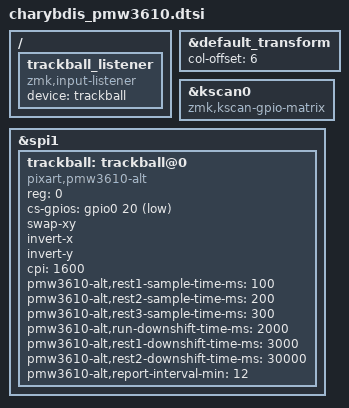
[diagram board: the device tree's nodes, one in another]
#include "charybdis.dtsi"
// #include "charybdis_pmw3610.dtsi"  <-- если в нём остался узел trackball, лучше убрать

&default_transform {
	col-offset = <6>;
};

&kscan0 {
	compatible = "zmk,kscan-gpio-matrix";
	// оставь свои col-gpios/row-gpios как было
};

// Трекбол на SPI1, не на SPI0
&spi1 {
    status = "okay";

    trackball: trackball@0 {
        compatible = "pixart,pmw3610-alt";
        reg = <0>;
        cs-gpios = <&gpio0 20 GPIO_ACTIVE_LOW>;

        swap-xy;
        invert-x;
        invert-y;

        cpi = <1600>;

        pmw3610-alt,rest1-sample-time-ms = <100>;
        pmw3610-alt,rest2-sample-time-ms = <200>;
        pmw3610-alt,rest3-sample-time-ms = <300>;
        pmw3610-alt,run-downshift-time-ms = <2000>;
        pmw3610-alt,rest1-downshift-time-ms = <3000>;
        pmw3610-alt,rest2-downshift-time-ms = <30000>;
        pmw3610-alt,report-interval-min = <12>;
    };
};

/ {
  trackball_listener {
    compatible = "zmk,input-listener";
    device = <&trackball>;
  };
};
